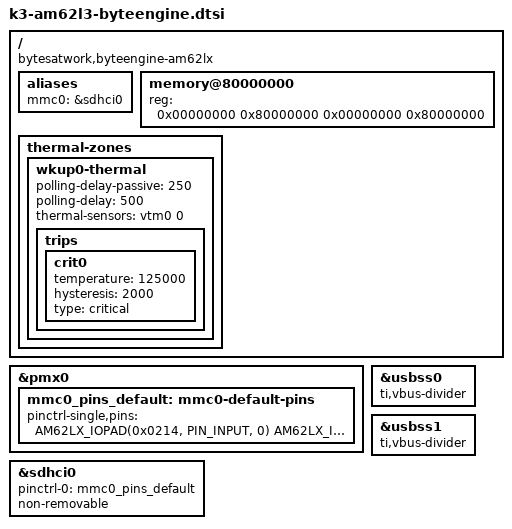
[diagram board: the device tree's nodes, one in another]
// SPDX-License-Identifier: GPL-2.0
/*
 * Copyright (C) 2026 bytesatwork AG - https://www.bytesatwork.io
 *
 * based on k3-am62l3-evm.dts:
 *
 * Copyright (C) 2021-2022 Texas Instruments Incorporated - https://www.ti.com/
 */

#include "k3-am62l3.dtsi"

/ {
	compatible = "bytesatwork,byteengine-am62lx", "ti,am62l3";

	aliases {
		mmc0 = &sdhci0;
	};

	memory@80000000 {
		/* 2G RAM */
		reg = <0x00000000 0x80000000 0x00000000 0x80000000>;
		device_type = "memory";
		bootph-all;
	};

	thermal-zones {
		wkup0-thermal {
			polling-delay-passive = <250>;	/* milliSeconds */
			polling-delay = <500>;		/* milliSeconds */
			thermal-sensors = <&vtm0 0>;

			trips {
				crit0 {
					temperature = <125000>;
					hysteresis = <2000>;
					type = "critical";
				};
			};
		};
	};
};

&pmx0 {
	mmc0_pins_default: mmc0-default-pins {
		pinctrl-single,pins = <
			AM62LX_IOPAD(0x0214, PIN_INPUT, 0) /* (D2) MMC0_CMD */
			AM62LX_IOPAD(0x020c, PIN_OUTPUT, 0) /* (B2) MMC0_CLK */
			AM62LX_IOPAD(0x0208, PIN_INPUT, 0) /* (D3) MMC0_DAT0 */
			AM62LX_IOPAD(0x0204, PIN_INPUT_PULLUP, 0) /* (D4) MMC0_DAT1 */
			AM62LX_IOPAD(0x0200, PIN_INPUT_PULLUP, 0) /* (C1) MMC0_DAT2 */
			AM62LX_IOPAD(0x01fc, PIN_INPUT_PULLUP, 0) /* (C2) MMC0_DAT3 */
			AM62LX_IOPAD(0x01f8, PIN_INPUT_PULLUP, 0) /* (C4) MMC0_DAT4 */
			AM62LX_IOPAD(0x01f4, PIN_INPUT_PULLUP, 0) /* (B3) MMC0_DAT5 */
			AM62LX_IOPAD(0x01f0, PIN_INPUT_PULLUP, 0) /* (A3) MMC0_DAT6 */
			AM62LX_IOPAD(0x01ec, PIN_INPUT_PULLUP, 0) /* (B4) MMC0_DAT7 */
		>;
		bootph-all;
	};
};

&sdhci0 {
	/* eMMC */
	pinctrl-names = "default";
	pinctrl-0 = <&mmc0_pins_default>;
	non-removable;
	status = "okay";
	bootph-all;
};

&usbss0 {
	status = "okay";
	ti,vbus-divider;
};

&usbss1 {
	status = "okay";
	ti,vbus-divider;
};
